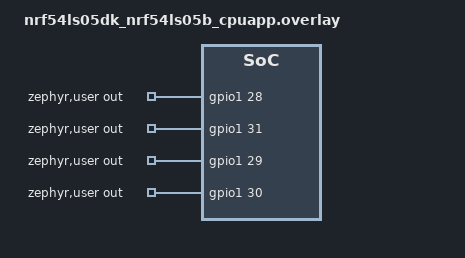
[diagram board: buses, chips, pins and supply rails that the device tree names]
/*
 * Copyright (c) 2025 Nordic Semiconductor ASA
 *
 * SPDX-License-Identifier: LicenseRef-Nordic-5-Clause
 */

/ {
	/* Test requirements:
	 * No other driver on out-gpios[n]
	 */
	zephyr,user {
		out-gpios = <&gpio1 28 GPIO_ACTIVE_HIGH>, <&gpio1 31 GPIO_ACTIVE_HIGH>,
			<&gpio1 29 GPIO_ACTIVE_HIGH>, <&gpio1 30 GPIO_ACTIVE_HIGH>;
	};
};

&gpio1 {
	status = "okay";
};

&tampc {
	swd-pins-as-gpios;
};
